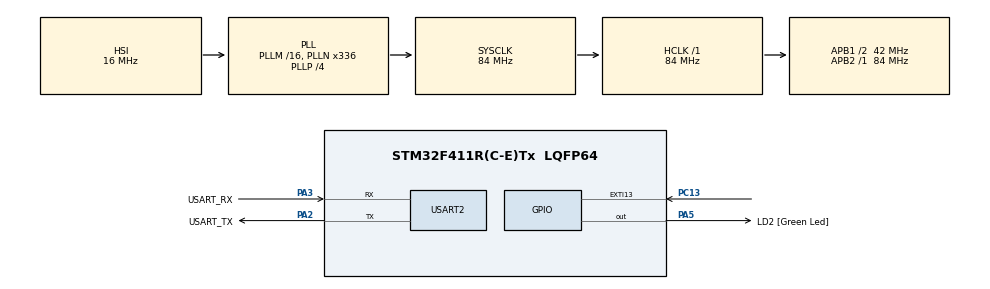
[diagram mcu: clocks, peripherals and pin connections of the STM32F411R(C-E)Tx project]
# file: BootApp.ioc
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FREERTOS.INCLUDE_pcTaskGetTaskName=1
FREERTOS.INCLUDE_uxTaskGetStackHighWaterMark2=1
FREERTOS.INCLUDE_vTaskCleanUpResources=1
FREERTOS.INCLUDE_xEventGroupSetBitFromISR=1
FREERTOS.INCLUDE_xSemaphoreGetMutexHolder=1
FREERTOS.INCLUDE_xTaskAbortDelay=1
FREERTOS.INCLUDE_xTaskGetHandle=1
FREERTOS.Tasks01=Button,24,256,StartButtonTask,Default,NULL,Dynamic,NULL,NULL;Blink,24,256,StartBlinkTask,Default,NULL,Dynamic,NULL,NULL
FREERTOS.configUSE_NEWLIB_REENTRANT=1
FREERTOS.configUSE_STATS_FORMATTING_FUNCTIONS=1
Mcu.Family=STM32F4
Mcu.Name=STM32F411R(C-E)Tx
Mcu.Package=LQFP64
NVIC.EXTI15_10_IRQn=true\:5\:0\:false\:false\:true\:true\:true\:true\:true
NVIC.PriorityGroup=NVIC_PRIORITYGROUP_4
NVIC.TIM5_IRQn=true\:15\:0\:false\:false\:true\:false\:false\:true\:true
NVIC.TimeBase=TIM5_IRQn
NVIC.TimeBaseIP=TIM5
NVIC.USART2_IRQn=true\:5\:0\:false\:false\:true\:true\:true\:true\:true
PA13.GPIO_Label=TMS
PA13.Mode=Serial_Wire
PA13.Signal=SYS_JTMS-SWDIO
PA14.GPIO_Label=TCK
PA14.Mode=Serial_Wire
PA14.Signal=SYS_JTCK-SWCLK
PA2.GPIO_Label=USART_TX
PA2.Mode=Asynchronous
PA2.Signal=USART2_TX
PA3.GPIO_Label=USART_RX
PA3.Mode=Asynchronous
PA3.Signal=USART2_RX
PA5.GPIO_Label=LD2 [Green Led]
PA5.Signal=GPIO_Output
PB3.GPIO_Label=SWO
PB3.Signal=SYS_JTDO-SWO
PC13-ANTI_TAMP.Signal=GPXTI13
PC14-OSC32_IN.Mode=LSE-External-Oscillator
PC14-OSC32_IN.Signal=RCC_OSC32_IN
PC15-OSC32_OUT.Mode=LSE-External-Oscillator
PC15-OSC32_OUT.Signal=RCC_OSC32_OUT
PH0\ -\ OSC_IN.Mode=HSE-External-Clock-Source
PH0\ -\ OSC_IN.Signal=RCC_OSC_IN
PH1\ -\ OSC_OUT.Mode=HSE-External-Clock-Source
PH1\ -\ OSC_OUT.Signal=RCC_OSC_OUT
ProjectManager.HeapSize=0x200
ProjectManager.StackSize=0x400
ProjectManager.TargetToolchain=STM32CubeIDE
RCC.48MHZClocksFreq_Value=84000000
RCC.AHBFreq_Value=84000000
RCC.APB1CLKDivider=RCC_HCLK_DIV2
RCC.APB1Freq_Value=42000000
RCC.APB1TimFreq_Value=84000000
RCC.APB2Freq_Value=84000000
RCC.APB2TimFreq_Value=84000000
RCC.CortexFreq_Value=84000000
RCC.FLatency-AdvancedSettings=FLASH_LATENCY_2
RCC.HCLKFreq_Value=84000000
RCC.HSE_VALUE=8000000
RCC.HSI_VALUE=16000000
RCC.PLLN=336
RCC.PLLP=RCC_PLLP_DIV4
RCC.SYSCLKFreq_VALUE=84000000
RCC.SYSCLKSource=RCC_SYSCLKSOURCE_PLLCLK
RCC.VCOOutputFreq_Value=336000000
USART2.VirtualMode=VM_ASYNC
VP_FREERTOS_VS_CMSIS_V2.Mode=CMSIS_V2
VP_SYS_VS_tim5.Mode=TIM5
board=NUCLEO-F411RE

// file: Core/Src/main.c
/* USER CODE BEGIN Header */
/**
  ******************************************************************************
  * @file           : main.c
  * @brief          : Main program body
  ******************************************************************************
  * @attention
  *
  * Copyright (c) 2026 STMicroelectronics.
  * All rights reserved.
  *
  * This software is licensed under terms that can be found in the LICENSE file
  * in the root directory of this software component.
  * If no LICENSE file comes with this software, it is provided AS-IS.
  *
  ******************************************************************************
  */
/* USER CODE END Header */
#include "main.h"
#include "cmsis_os.h"

/* USER CODE BEGIN Includes */
#include "uart_log.h"
#include "app_freertos.h"
/* USER CODE END Includes */

UART_HandleTypeDef huart2;
uint8_t rx_byte;
char rx_buffer[64];
uint8_t rx_index = 0;

void SystemClock_Config(void);
static void MX_GPIO_Init(void);
static void MX_USART2_UART_Init(void);

int main(void)
{

  /* USER CODE BEGIN 1 */
  SCB->VTOR = 0x08008000;   /* Repointer VTRO a l'addresse de l'app*/
   __DSB();
   __ISB();
  /* USER CODE END 1 */

  /* MCU Configuration--------------------------------------------------------*/

  /* Reset of all peripherals, Initializes the Flash interface and the Systick. */
  HAL_Init();

  /* Configure the system clock */
  SystemClock_Config();

  /* Initialize all configured peripherals */
  MX_GPIO_Init();
  MX_USART2_UART_Init();

  /* Init scheduler */
  osKernelInitialize();

  /* Create the thread(s) */
  /* creation of Button */

  /* USER CODE BEGIN RTOS_EVENTS */
  uart_log_init();
  MX_FREERTOS_Init();
  HAL_UART_Receive_IT(&huart2, &rx_byte, 1);   // ← ICI
   /* crée le mutex de log avant le démarrage du scheduler */
  /* USER CODE END RTOS_EVENTS */

  /* Start scheduler */
  osKernelStart();

  /* We should never get here as control is now taken by the scheduler */

  /* Infinite loop */
  while (1)
  {

  }
}

void SystemClock_Config(void)
{
  RCC_OscInitTypeDef RCC_OscInitStruct = {0};
  RCC_ClkInitTypeDef RCC_ClkInitStruct = {0};

  /** Configure the main internal regulator output voltage
  */
  __HAL_RCC_PWR_CLK_ENABLE();
  __HAL_PWR_VOLTAGESCALING_CONFIG(PWR_REGULATOR_VOLTAGE_SCALE1);

  /** Initializes the RCC Oscillators according to the specified parameters
  * in the RCC_OscInitTypeDef structure.
  */
  RCC_OscInitStruct.OscillatorType = RCC_OSCILLATORTYPE_HSI;
  RCC_OscInitStruct.HSIState = RCC_HSI_ON;
  RCC_OscInitStruct.HSICalibrationValue = RCC_HSICALIBRATION_DEFAULT;
  RCC_OscInitStruct.PLL.PLLState = RCC_PLL_ON;
  RCC_OscInitStruct.PLL.PLLSource = RCC_PLLSOURCE_HSI;
  RCC_OscInitStruct.PLL.PLLM = 16;
  RCC_OscInitStruct.PLL.PLLN = 336;
  RCC_OscInitStruct.PLL.PLLP = RCC_PLLP_DIV4;
  RCC_OscInitStruct.PLL.PLLQ = 4;
  if (HAL_RCC_OscConfig(&RCC_OscInitStruct) != HAL_OK)
  {
    Error_Handler();
  }

  /** Initializes the CPU, AHB and APB buses clocks
  */
  RCC_ClkInitStruct.ClockType = RCC_CLOCKTYPE_HCLK|RCC_CLOCKTYPE_SYSCLK
                              |RCC_CLOCKTYPE_PCLK1|RCC_CLOCKTYPE_PCLK2;
  RCC_ClkInitStruct.SYSCLKSource = RCC_SYSCLKSOURCE_PLLCLK;
  RCC_ClkInitStruct.AHBCLKDivider = RCC_SYSCLK_DIV1;
  RCC_ClkInitStruct.APB1CLKDivider = RCC_HCLK_DIV2;
  RCC_ClkInitStruct.APB2CLKDivider = RCC_HCLK_DIV1;

  if (HAL_RCC_ClockConfig(&RCC_ClkInitStruct, FLASH_LATENCY_2) != HAL_OK)
  {
    Error_Handler();
  }
}

static void MX_USART2_UART_Init(void)
{

  huart2.Instance = USART2;
  huart2.Init.BaudRate = 115200;
  huart2.Init.WordLength = UART_WORDLENGTH_8B;
  huart2.Init.StopBits = UART_STOPBITS_1;
  huart2.Init.Parity = UART_PARITY_NONE;
  huart2.Init.Mode = UART_MODE_TX_RX;
  huart2.Init.HwFlowCtl = UART_HWCONTROL_NONE;
  huart2.Init.OverSampling = UART_OVERSAMPLING_16;
  if (HAL_UART_Init(&huart2) != HAL_OK)
  {
    Error_Handler();
  }

}

static void MX_GPIO_Init(void)
{
  GPIO_InitTypeDef GPIO_InitStruct = {0};

  /* GPIO Ports Clock Enable */
  __HAL_RCC_GPIOC_CLK_ENABLE();
  __HAL_RCC_GPIOH_CLK_ENABLE();
  __HAL_RCC_GPIOA_CLK_ENABLE();
  __HAL_RCC_GPIOB_CLK_ENABLE();

  /*Configure GPIO pin Output Level */
  HAL_GPIO_WritePin(LD2_GPIO_Port, LD2_Pin, GPIO_PIN_RESET);

  /*Configure GPIO pin : PC13 */
  GPIO_InitStruct.Pin = GPIO_PIN_13;
  GPIO_InitStruct.Mode = GPIO_MODE_IT_RISING;
  GPIO_InitStruct.Pull = GPIO_NOPULL;
  HAL_GPIO_Init(GPIOC, &GPIO_InitStruct);

  /*Configure GPIO pin : LD2_Pin */
  GPIO_InitStruct.Pin = LD2_Pin;
  GPIO_InitStruct.Mode = GPIO_MODE_OUTPUT_PP;
  GPIO_InitStruct.Pull = GPIO_NOPULL;
  GPIO_InitStruct.Speed = GPIO_SPEED_FREQ_LOW;
  HAL_GPIO_Init(LD2_GPIO_Port, &GPIO_InitStruct);

  /* EXTI interrupt init*/
  HAL_NVIC_SetPriority(EXTI15_10_IRQn, 5, 0);
  HAL_NVIC_EnableIRQ(EXTI15_10_IRQn);

}

void HAL_TIM_PeriodElapsedCallback(TIM_HandleTypeDef *htim)
{
  if (htim->Instance == TIM5)
  {
    HAL_IncTick();
  }
}

void HAL_GPIO_EXTI_Callback(uint16_t GPIO_Pin) {
    if (GPIO_Pin == GPIO_PIN_13) {
        osSemaphoreRelease(ButtonSem);
    }
}

void HAL_UART_RxCpltCallback(UART_HandleTypeDef *huart)
{
    if (huart->Instance == USART2) {

        // CAS 1 : Entrée tapée → fin de commande
        if (rx_byte == '\n' || rx_byte == '\r') {
            rx_buffer[rx_index] = '\0';
            osMessageQueuePut(UartQueue, rx_buffer, 0, 0);
            rx_index = 0;
        }
        // CAS 2 : lettre normale → accumuler
        else if (rx_index < sizeof(rx_buffer) - 1) {
            rx_buffer[rx_index++] = rx_byte;
        }

        // Toujours : réarmer pour le prochain octet
        HAL_UART_Receive_IT(&huart2, &rx_byte, 1);
    }
}

void Error_Handler(void)
{
  __disable_irq();
  while (1)
  {
  }
}

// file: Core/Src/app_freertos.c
#include "app_freertos.h"
#include "main.h"
#include "uart_log.h"
#include <string.h>

/* Handles définis ici */
osThreadId_t BlinkHandle;
osThreadId_t ButtonHandle;
osThreadId_t UartButtonHandle;
osSemaphoreId_t ButtonSem;
osMessageQueueId_t UartQueue;

/* Attributs des tâches */
const osThreadAttr_t Blink_attributes = {
    .name = "Blink",
    .stack_size = 128 * 4,
    .priority = (osPriority_t) osPriorityNormal,
};

const osThreadAttr_t Button_attributes = {
    .name = "Button",
    .stack_size = 128 * 4,
    .priority = (osPriority_t) osPriorityNormal,
};

const osThreadAttr_t UartBlink_attributes = {
    .name = "UartBlink",
    .stack_size = 128 * 4,
    .priority = (osPriority_t) osPriorityNormal,
};

/**
 * @brief Initialise toutes les tâches, sémaphores, queues FreeRTOS.
 *        Appelé depuis main() avant osKernelStart().
 */
void MX_FREERTOS_Init(void)
{
    /* Sémaphores */
    ButtonSem = osSemaphoreNew(1, 0, NULL);
    UartQueue = osMessageQueueNew(10, 64, NULL);

    /* Tâches */
    BlinkHandle  = osThreadNew(StartBlinkTask,  NULL, &Blink_attributes);
    ButtonHandle = osThreadNew(StartButtonTask, NULL, &Button_attributes);

}

/* ===== Implémentations des tâches ===== */

void StartBlinkTask(void *argument)
{
    for (;;) {
        HAL_GPIO_TogglePin(LD2_GPIO_Port, LD2_Pin);
        LOG_BLINK("LED BLINKS");
        osDelay(500);
    }
}

void StartButtonTask(void *argument)
{
    for (;;) {
        osSemaphoreAcquire(ButtonSem, osWaitForever);
        LOG_INFO("Bouton pressé !");
    }
}

void StartUartBlinkTask(void *argument)
{
    char received[64];
    for (;;) {
        // Attend une commande complète
        osMessageQueueGet(UartQueue, received, NULL, osWaitForever);

        LOG_INFO("Commande reçue: %s", received);

        if (strcmp(received, "LED_ON") == 0) {
            HAL_GPIO_WritePin(LD2_GPIO_Port, LD2_Pin, GPIO_PIN_SET);
            LOG_INFO("LED allumée");
        }
        else if (strcmp(received, "LED_OFF") == 0) {
            HAL_GPIO_WritePin(LD2_GPIO_Port, LD2_Pin, GPIO_PIN_RESET);
            LOG_INFO("LED éteinte");
        }
        else {
            LOG_WARN("Commande inconnue : %s", received);
        }
    }
}
